# PIC32CK2051SG00064 register map
Vendor: Microchip Technology; Series: PIC32CKSG00; File version: 0
CPU: CM33 r0p0, little endian, MPU, FPU, DSP, 3 interrupt priority bits, 158 interrupts, 19 SAU regions
Registers are 32-bit, read-write, reset 0x0 unless marked. A register's access mark holds for its fields unless they carry their own. Offsets are from the block's base; [hi:lo] are bit positions; lines under a group give offsets from that group; {n}, {i} and the like mark numbered series; <NAME> marks a mode.

## FREQM — Frequency Meter
Base 0x44014000; register names take the prefix FREQM_
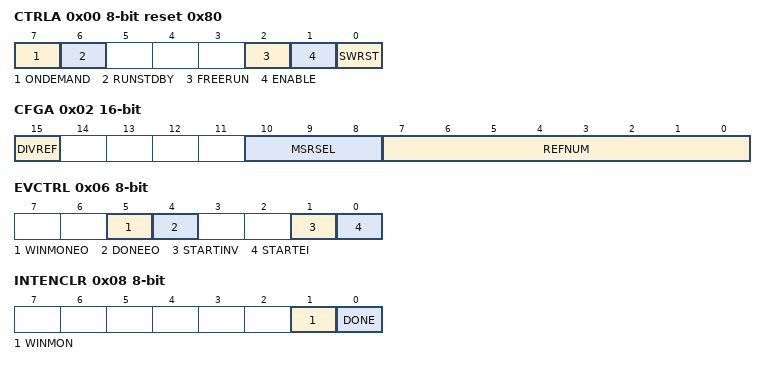
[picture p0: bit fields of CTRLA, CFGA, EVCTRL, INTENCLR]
0x00 CTRLA 8-bit reset 0x80 — Control A Register
  [7] ONDEMAND — On Demand Control
  [6] RUNSTDBY — Run In Standby
  [2] FREERUN — Free Running Mode
  [1] ENABLE
  [0] SWRST — Software Reset
0x01 CTRLB 8-bit wo — Control B Register
  [0] START — Start Measurement
0x02 CFGA 16-bit — Config A Register
  [15] DIVREF — Divide Reference Clock
    0=DIV1 (The reference clock is divided by 1); 1=DIV8 (The reference clock is divided by 8)
  [10:8] MSRSEL — Measurement Clock Selection
    0=GCLK (GCLK Input Clock); 1=CPU (CPU Input Clock)
  [7:0] REFNUM — Number of Reference Clock Cycles
0x04 CTRLC 8-bit — Control C Register
  [2:0] WINMODE — Window Monitor Mode
    0=DISABLE (No window mode (default)); 1=MODE1 (VALUE > WINLT); 2=MODE2 (VALUE < WINUT); 3=MODE3 (WINLT < VALUE < WINUT); 4=MODE4 (!(WINLT < VALUE < WINUT))
0x06 EVCTRL 8-bit — Event Control Register
  [5] WINMONEO — Window Monitor Event Out
  [4] DONEEO — Measurement Done Event Out
  [1] STARTINV — Start Measurement Event Invert Enable
  [0] STARTEI — Start Measurement Event Input Enable
0x08 INTENCLR 8-bit — Interrupt Enable Clear Register
  [1] WINMON — Window Monitor Interrupt Disable
  [0] DONE — Measurement Done Interrupt Disable
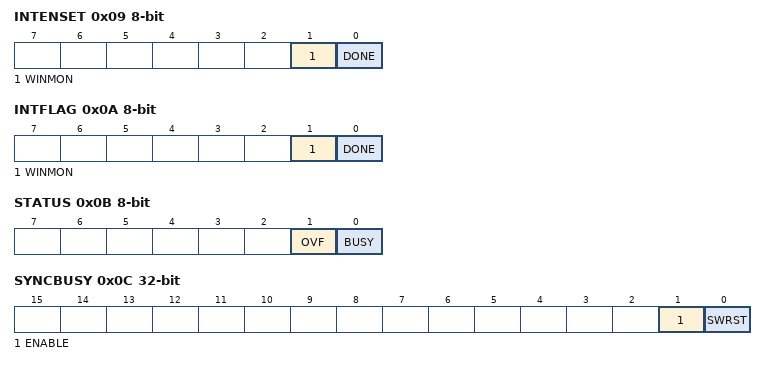
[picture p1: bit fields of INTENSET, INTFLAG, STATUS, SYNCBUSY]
0x09 INTENSET 8-bit — Interrupt Enable Set Register
  [1] WINMON — Window Monitor Interrupt Enable
  [0] DONE — Measurement Done Interrupt Enable
0x0A INTFLAG 8-bit — Interrupt Flag Register
  [1] WINMON — Window Monitor
  [0] DONE — Measurement Done
0x0B STATUS 8-bit
  [1] OVF — Sticky Count Value Overflow
  [0] BUSY — FREQM Status
0x0C SYNCBUSY ro — Synchronization Busy Register
  [1] ENABLE
  [0] SWRST — Software Reset
0x10 VALUE ro — Count Value Register
  [23:0] VALUE — Measurement Value
0x20 WINLT — Window Monitor Lower Threshold
  [23:0] WINLT — Window Lower Threshold
0x24 WINUT — Window Monitor Upper Threshold
  [23:0] WINUT — Window Upper Threshold

## GCLK — Generic Clock Generator
Base 0x44010000; register names take the prefix GCLK_
0x00 CTRLA 8-bit — Control
  [0] SWRST — Software Reset
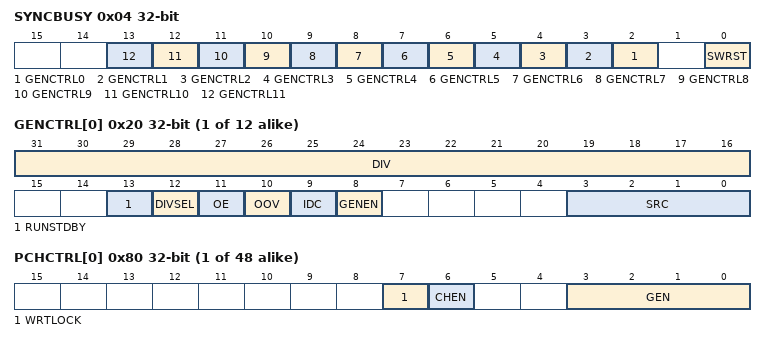
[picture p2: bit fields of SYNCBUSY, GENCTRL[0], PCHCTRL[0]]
0x04 SYNCBUSY ro — Synchronization Busy
  [n+2] GENCTRL{n} (n=0..11) — Generic Clock Generator Control {n} Synchronization Busy bit
  [0] SWRST — Software Reset Synchronization Busy bit
{0x20+4i} GENCTRL[{i}] (i=0..11) — Generic Clock Generator Control
  [31:16] DIV — Division Factor
  [13] RUNSTDBY — Run in Standby
  [12] DIVSEL — Divide Selection
    0=DIV1 (Divide input directly by divider factor); 1=DIV2 (Divide input by 2^(divider factor+ 1))
  [11] OE — Output Enable
  [10] OOV — Output Off Value
  [9] IDC — Improve Duty Cycle
  [8] GENEN — Generic Clock Generator Enable
  [3:0] SRC — Source Select
    0=XOSC (XOSC0 oscillator output); 1=GCLKIN (Generator input pad); 2=GCLKGEN1 (Generic clock generator 1 output); 3=OSCULP32K (OSCULP32K oscillator output); 4=XOSC32K (XOSC32K oscillator output); 5=DFLL (DFLL output); 6=PLL0_0 (Frac Divider PLL0 output 0); {v}=PLL0_{v-6} (PLL0 output {v-6}) (v=7..11)
{0x80+4i} PCHCTRL[{i}] (i=0..47) — Peripheral Clock Control
  [7] WRTLOCK — Write Lock
  [6] CHEN — Channel Enable
  [3:0] GEN — Generic Clock Generator
    {v}=GCLK{v} (Generic clock generator {v}) (v=0..11)

## HMATRIX — HSB Matrix
Base 0x44806000; register names take the prefix HMATRIX2_
{0x0+4i} MCFG[{i}] (i=0..15) reset 0x2 — Master Configuration
  [2:0] ULBT — Undefined Length Burst Type
    0=INFINITE (Infinite Length); 1=SINGLE (Single Access); 2=FOUR_BEAT (Four Beat Burst); 3=EIGHT_BEAT (Eight Beat Burst); 4=SIXTEEN_BEAT (Sixteen Beat Burst)
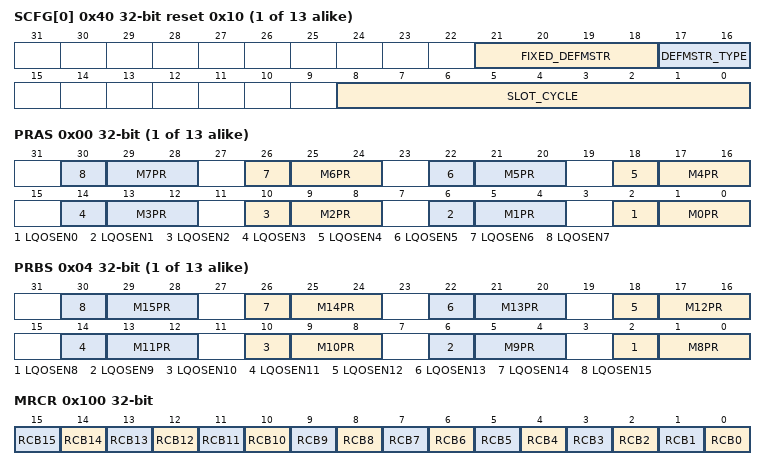
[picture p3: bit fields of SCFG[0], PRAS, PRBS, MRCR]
{0x40+4i} SCFG[{i}] (i=0..12) reset 0x10 — Slave Configuration
  [21:18] FIXED_DEFMSTR — Fixed Index of Default Master
  [17:16] DEFMSTR_TYPE — Default Master Type
    0=NO_DEFAULT (No Default Master. At the end of current slave access, if no other master request is pending, the slave is deconnected from all masters. This resusts in having a one cycle latency for the first transfer of a burst.); 1=LAST_DEFAULT (Last Default Master At the end of current slave access, if no other master request is pending, the slave stay connected with the last master havingaccessed it.This resusts in not having the one cycle latency when the last master re-trying access on the slave.); 2=FIXED_DEFAULT (Fixed Default Master At the end of current slave access, if no other master request is pending, the slave connects with fixed master which numberis in FIXED_DEFMSTR register.This resusts in not having the one cycle latency when the fixed master re-trying access on the slave.)
  [8:0] SLOT_CYCLE — Maximum Number of Allowed Cycles for a Burst
{0x80+8i} PRS[{i}] (i=0..12) group
  0x00 PRAS — Priority A for Slave
    [4n+2] LQOSEN{n} (n=0..7) — Latency Quality Of Service Enable for Master {n}
    [4n+1:4n] M{n}PR (n=0..7) — Master {n} Priority
  0x04 PRBS — Priority B for Slave
    [4n-30] LQOSEN{n} (n=8..15) — Latency Quality Of Service Enable for Master {n}
    [4n-31:4n-32] M{n}PR (n=8..15) — Master {n} Priority
0x100 MRCR — Master Remap Control
  [all] fields
    0=DIS (Disable remapped address decoding for master); 1=ENA (Enable remapped address decoding for master)
  [n] RCB{n} (n=0..15) — Remap Command Bit for Master {n}
{0x110+4i} SFR[{i}] (i=0..12) — Special Function
  [31:0] SFR — Special Function Register
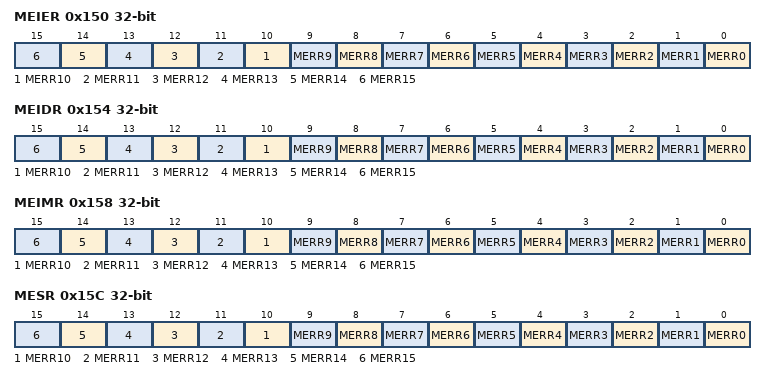
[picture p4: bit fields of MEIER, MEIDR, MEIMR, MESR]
0x150 MEIER wo — Master Error Interrupt Enable
  [n] MERR{n} (n=0..15) — Master {n} Access Error
0x154 MEIDR wo — Master Error Interrupt Disable
  [n] MERR{n} (n=0..15) — Master {n} Access Error
0x158 MEIMR ro — Master Error Interrupt Mask
  [n] MERR{n} (n=0..15) — Master {n} Access Error
0x15C MESR ro — Master Error Status
  [n] MERR{n} (n=0..15) — Master {n} Access Error
{0x160+4i} MEAR[{i}] (i=0..15) ro — Master Error Address

## Notices in the file
Copyright (c) 2022 Microchip Technology Inc.
SPDX-License-Identifier: Apache-2.0
Licensed under the Apache License, Version 2.0 (the "License");
you may not use this file except in compliance with the License.
You may obtain a copy of the License at
http://www.apache.org/licenses/LICENSE-2.0
Unless required by applicable law or agreed to in writing, software
distributed under the License is distributed on an "AS IS" BASIS,
WITHOUT WARRANTIES OR CONDITIONS OF ANY KIND, either express or implied.
See the License for the specific language governing permissions and
limitations under the License.
